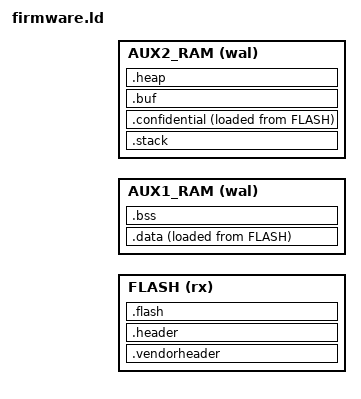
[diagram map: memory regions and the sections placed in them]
INCLUDE "./embed/sys/linker/stm32u58/memory.ld";

ENTRY(reset_handler)

MEMORY {
  FLASH  (rx)  : ORIGIN = KERNEL_START, LENGTH = FIRMWARE_MAXSIZE
  AUX1_RAM (wal) : ORIGIN = AUX1_RAM_START, LENGTH = AUX1_RAM_SIZE
  AUX2_RAM (wal) : ORIGIN = AUX2_RAM_START, LENGTH = AUX2_RAM_SIZE
}

_stack_section_start = ADDR(.stack);
_stack_section_end = ADDR(.stack) + SIZEOF(.stack);
_stack_section_size = SIZEOF(.stack);

_data_section_loadaddr = LOADADDR(.data);
_data_section_start = ADDR(.data);
_data_section_end = ADDR(.data) + SIZEOF(.data);

_bss_section_start = ADDR(.bss);
_bss_section_end = ADDR(.bss) + SIZEOF(.bss);

_confidential_section_loadaddr = LOADADDR(.confidential);
_confidential_section_start = ADDR(.confidential);
_confidential_section_end = ADDR(.confidential) + SIZEOF(.confidential);

_codelen = SIZEOF(.flash) + SIZEOF(.data) + SIZEOF(.confidential);
_flash_start = ORIGIN(FLASH);
_flash_end = ORIGIN(FLASH) + LENGTH(FLASH);
_heap_start = ADDR(.heap);
_heap_end = ADDR(.heap) + SIZEOF(.heap);

SECTIONS {
  .vendorheader : ALIGN(4) {
    KEEP(*(.vendorheader))
  } >FLASH AT>FLASH

  .header : ALIGN(4) {
    KEEP(*(.header));
    . = ALIGN(CODE_ALIGNMENT);
  } >FLASH AT>FLASH

  .flash : ALIGN(CODE_ALIGNMENT) {
    KEEP(*(.kernel));
    . = ALIGN(COREAPP_ALIGNMENT);
    KEEP(*(.vector_table));
    . = ALIGN(4);
    *(.text*);
    . = ALIGN(4);
    *(.rodata*);
    . = ALIGN(512);
  } >FLASH AT>FLASH

  .data : ALIGN(4) {
    *(.data*);
    . = ALIGN(512);
  } >AUX1_RAM AT>FLASH

  /DISCARD/ : {
    *(.ARM.exidx*);
  }

  .bss : ALIGN(4) {
    *(.no_dma_buffers*);
    *(.bss*);
    . = ALIGN(4);
  } >AUX1_RAM

  .stack : ALIGN(8) {
    . = 32K; /* Overflow causes UsageFault */
  } >AUX2_RAM

  .confidential : ALIGN(512) {
    *(.confidential*);
    . = ALIGN(512);
  } >AUX2_RAM AT>FLASH

  .buf : ALIGN(4) {
    *(.buf*);
    . = ALIGN(4);
  } >AUX2_RAM

  .heap : ALIGN(4) {
    . = 37K; /* this acts as a build time assertion that at least this much memory is available for heap use */
    . = ABSOLUTE(ORIGIN(AUX2_RAM) + LENGTH(AUX2_RAM)); /* this explicitly sets the end of the heap */
  } >AUX2_RAM
}
